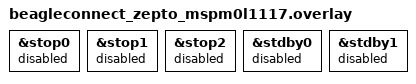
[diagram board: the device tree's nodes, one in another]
/*
 * This SoC's STOP/STANDBY power states gate the clock that also feeds the
 * ARM SysTick Zephyr uses as its kernel tick source (see
 * soc/ti/mspm/common/power.c: pm_state_set() for stop0/1/2 and stdby0/1).
 * There is no low-power wake timer wired up yet to bring the CPU back out
 * of those states, so once the idle period exceeds their min-residency-us
 * (5-10 ms -- see dts/arm/ti/mspm0/l/mspm0l.dtsi), Zephyr's PM policy picks
 * one of them and the board never wakes back up.
 *
 * Disable STOP/STANDBY here and keep only the RUN-sleep states (run0/1/2),
 * which clock-gate just the CPU core via WFI and leave SysTick running --
 * safe, and still saves power on every idle period.
 */

&stop0 {
	status = "disabled";
};

&stop1 {
	status = "disabled";
};

&stop2 {
	status = "disabled";
};

&stdby0 {
	status = "disabled";
};

&stdby1 {
	status = "disabled";
};
